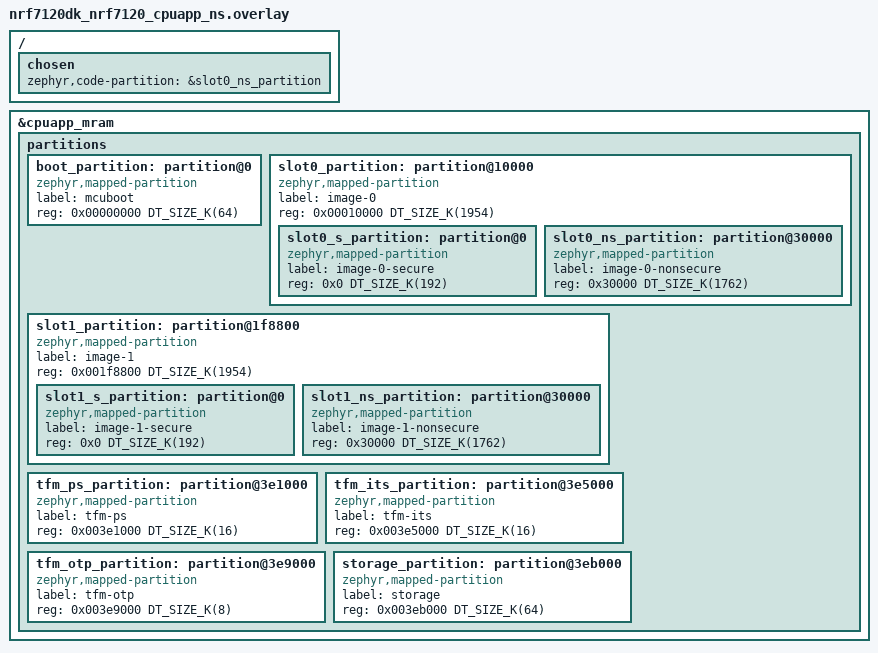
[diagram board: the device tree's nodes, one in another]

/*
 * Copyright (c) 2026 Nordic Semiconductor
 * SPDX-License-Identifier: Apache-2.0
 */

&cpuapp_mram {
	/delete-node/ partitions;
};

&cpuapp_mram {
	/*
	 * Default NVM layout on NRF7120 Application MCU with BL2:
	 * This layout matches (by necessity) that in the TF-M repository:
	 *
	 * 0x0000_0000 Boot Partition (64 KB)
	 *
	 * 0x0001_0000 Primary image area (1954 KB):
	 *   - 0x0001_0000 Secure image primary (192 KB)
	 *   - 0x0004_0000 Non-secure image primary (1762 KB)
	 *
	 * 0x001F_8800 Secondary image area (1954 KB):
	 *   - 0x001F_8800 Secure image secondary (192 KB)
	 *   - 0x0022_8800 Non-secure image secondary (1762 KB)
	 *
	 * 0x003E_1000 Protected Storage Area (16 KB)
	 * 0x003E_5000 Internal Trusted Storage Area (16 KB)
	 * 0x003E_9000 OTP / NV counters area (8 KB)
	 *
	 * 0x003E_B000 Non-secure storage, used when built with NRF_NS_STORAGE=ON,
	 *             otherwise unused (64 KB)
	 */
	partitions {
		#address-cells = <1>;
		#size-cells = <1>;
		ranges;

		/* This static layout needs to be the same with the upstream TF-M layout in the
		 * header flash_layout.h of the relevant platform. Any updates in the layout
		 * needs to happen both in the flash_layout.h and in this file at the same time.
		 */

		boot_partition: partition@0 {
			compatible = "zephyr,mapped-partition";
			label = "mcuboot";
			reg = <0x00000000 DT_SIZE_K(64)>;
		};

		slot0_partition: partition@10000 {
			compatible = "zephyr,mapped-partition";
			label = "image-0";
			reg = <0x00010000 DT_SIZE_K(1954)>;
			ranges = <0x0 0x00010000 DT_SIZE_K(1954)>;
			#address-cells = <1>;
			#size-cells = <1>;

			slot0_s_partition: partition@0 {
				compatible = "zephyr,mapped-partition";
				label = "image-0-secure";
				reg = <0x0 DT_SIZE_K(192)>;
			};

			slot0_ns_partition: partition@30000 {
				compatible = "zephyr,mapped-partition";
				label = "image-0-nonsecure";
				reg = <0x30000 DT_SIZE_K(1762)>;
			};
		};

		slot1_partition: partition@1f8800 {
			compatible = "zephyr,mapped-partition";
			label = "image-1";
			reg = <0x001f8800 DT_SIZE_K(1954)>;
			ranges = <0x0 0x001f8800 DT_SIZE_K(1954)>;
			#address-cells = <1>;
			#size-cells = <1>;

			slot1_s_partition: partition@0 {
				compatible = "zephyr,mapped-partition";
				label = "image-1-secure";
				reg = <0x0 DT_SIZE_K(192)>;
			};

			slot1_ns_partition: partition@30000 {
				compatible = "zephyr,mapped-partition";
				label = "image-1-nonsecure";
				reg = <0x30000 DT_SIZE_K(1762)>;
			};
		};

		tfm_ps_partition: partition@3e1000 {
			compatible = "zephyr,mapped-partition";
			label = "tfm-ps";
			reg = <0x003e1000 DT_SIZE_K(16)>;
		};

		tfm_its_partition: partition@3e5000 {
			compatible = "zephyr,mapped-partition";
			label = "tfm-its";
			reg = <0x003e5000 DT_SIZE_K(16)>;
		};

		tfm_otp_partition: partition@3e9000 {
			compatible = "zephyr,mapped-partition";
			label = "tfm-otp";
			reg = <0x003e9000 DT_SIZE_K(8)>;
		};

		storage_partition: partition@3eb000 {
			compatible = "zephyr,mapped-partition";
			label = "storage";
			reg = <0x003eb000 DT_SIZE_K(64)>;
		};
	};
};

/ {
	chosen {
		zephyr,code-partition = &slot0_ns_partition;
	};
};
